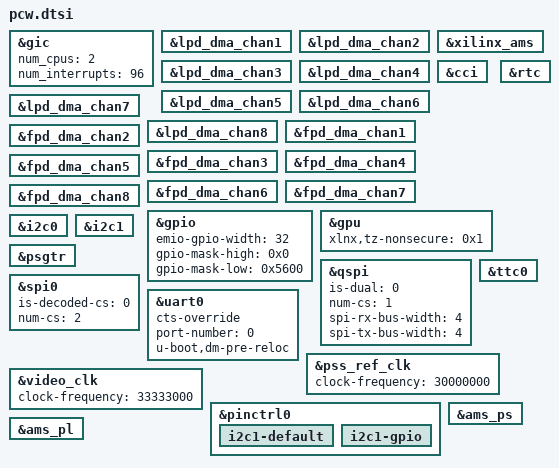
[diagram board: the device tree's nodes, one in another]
/*
 * CAUTION: This file is automatically generated by Xilinx.
 * Version: XSCT 2022.2
 * Today is: Wed Feb 28 11:40:46 2024
 */


&gic {
	num_cpus = <2>;
	num_interrupts = <96>;
};
&lpd_dma_chan1 {
	status = "okay";
};
&lpd_dma_chan2 {
	status = "okay";
};
&lpd_dma_chan3 {
	status = "okay";
};
&lpd_dma_chan4 {
	status = "okay";
};
&lpd_dma_chan5 {
	status = "okay";
};
&lpd_dma_chan6 {
	status = "okay";
};
&lpd_dma_chan7 {
	status = "okay";
};
&lpd_dma_chan8 {
	status = "okay";
};
&xilinx_ams {
	status = "okay";
};
&cci {
	status = "okay";
};
&fpd_dma_chan1 {
	status = "okay";
};
&fpd_dma_chan2 {
	status = "okay";
};
&fpd_dma_chan3 {
	status = "okay";
};
&fpd_dma_chan4 {
	status = "okay";
};
&fpd_dma_chan5 {
	status = "okay";
};
&fpd_dma_chan6 {
	status = "okay";
};
&fpd_dma_chan7 {
	status = "okay";
};
&fpd_dma_chan8 {
	status = "okay";
};
&gpio {
	emio-gpio-width = <32>;
	gpio-mask-high = <0x0>;
	gpio-mask-low = <0x5600>;
	status = "okay";
};
&gpu {
	status = "okay";
	xlnx,tz-nonsecure = <0x1>;
};
&i2c0 {
	status = "okay";
};
&i2c1 {
	status = "okay";
};
&qspi {
	is-dual = <0>;
	num-cs = <1>;
	spi-rx-bus-width = <4>;
	spi-tx-bus-width = <4>;
	status = "okay";
};
&rtc {
	status = "okay";
};
&psgtr {
	status = "okay";
};
&spi0 {
	is-decoded-cs = <0>;
	num-cs = <2>;
	status = "okay";
};
&ttc0 {
	status = "okay";
};
&uart0 {
	cts-override ;
	device_type = "serial";
	port-number = <0>;
	status = "okay";
	u-boot,dm-pre-reloc ;
};
&pss_ref_clk {
	clock-frequency = <30000000>;
};
&video_clk {
	clock-frequency = <33333000>;
};
&pinctrl0 {
	i2c1-default {
		/delete-node/ conf ;
		/delete-node/ mux ;
	};
	i2c1-gpio {
		/delete-node/ conf ;
		/delete-node/ mux ;
	};
};
&ams_ps {
	status = "okay";
};
&ams_pl {
	status = "okay";
};
